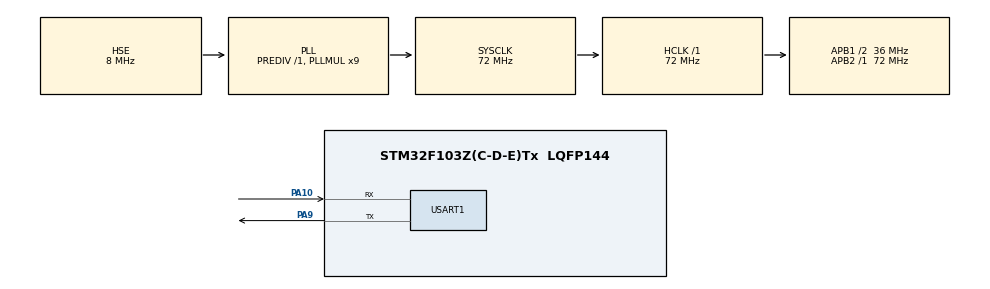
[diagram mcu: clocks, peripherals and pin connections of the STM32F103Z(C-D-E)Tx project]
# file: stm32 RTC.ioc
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Mcu.Family=STM32F1
Mcu.Name=STM32F103Z(C-D-E)Tx
Mcu.Package=LQFP144
NVIC.PriorityGroup=NVIC_PRIORITYGROUP_4
NVIC.RTC_Alarm_IRQn=true\:0\:0\:false\:false\:true\:true\:true
NVIC.RTC_IRQn=true\:0\:0\:false\:false\:true\:true\:true
NVIC.USART1_IRQn=true\:0\:0\:false\:false\:true\:true\:true
OSC_IN.Mode=HSE-External-Oscillator
OSC_IN.Signal=RCC_OSC_IN
OSC_OUT.Mode=HSE-External-Oscillator
OSC_OUT.Signal=RCC_OSC_OUT
PA10.Mode=Asynchronous
PA10.Signal=USART1_RX
PA9.Mode=Asynchronous
PA9.Signal=USART1_TX
ProjectManager.HeapSize=0x200
ProjectManager.StackSize=0x400
ProjectManager.TargetToolchain=MDK-ARM V5.32
RCC.AHBFreq_Value=72000000
RCC.APB1CLKDivider=RCC_HCLK_DIV2
RCC.APB1Freq_Value=36000000
RCC.APB1TimFreq_Value=72000000
RCC.APB2Freq_Value=72000000
RCC.APB2TimFreq_Value=72000000
RCC.HCLKFreq_Value=72000000
RCC.PLLMUL=RCC_PLL_MUL9
RCC.PLLSourceVirtual=RCC_PLLSOURCE_HSE
RCC.SYSCLKFreq_VALUE=72000000
RCC.SYSCLKSource=RCC_SYSCLKSOURCE_PLLCLK
RCC.USBFreq_Value=72000000
RTC.Date=14
RTC.Hours=10
RTC.WeekDay=RTC_WEEKDAY_SATURDAY
USART1.VirtualMode=VM_ASYNC
VP_RTC_VS_RTC_Activate.Mode=RTC_Enabled
VP_RTC_VS_RTC_Calendar.Mode=RTC_Calendar
VP_SYS_VS_ND.Mode=No_Debug
board=custom

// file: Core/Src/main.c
/* USER CODE BEGIN Header */
/**
  ******************************************************************************
  * @file           : main.c
  * @brief          : Main program body
  ******************************************************************************
  * @attention
  *
  * Copyright (c) 2023 STMicroelectronics.
  * All rights reserved.
  *
  * This software is licensed under terms that can be found in the LICENSE file
  * in the root directory of this software component.
  * If no LICENSE file comes with this software, it is provided AS-IS.
  *
  ******************************************************************************
  */
/* USER CODE END Header */
#include "main.h"
#include "rtc.h"
#include "usart.h"
#include "gpio.h"

/* USER CODE BEGIN Includes */
#include "stdio.h"
#include "string.h"
/* USER CODE END Includes */

/* USER CODE BEGIN PTD */
RTC_TimeTypeDef RtcTime;
RTC_DateTypeDef RtcDate;

const char LedMode1[8] = "kaishi";
const char LedMode2[11] = "chushihua";
const char LedMode3[14] = "shezhi12311111";
const char LedMode4[9] = "xianshi";

#define RXBUFFERSIZE  256     //最大接收字节数
char RxBuffer[RXBUFFERSIZE];   //接收数据
uint8_t aRxBuffer;			//接收中断缓冲
uint8_t Uart1_Rx_Cnt = 0;		//接收缓冲计数

/* USER CODE END PTD */

void SystemClock_Config(void);

int main(void)
{

  /* MCU Configuration--------------------------------------------------------*/

  /* Reset of all peripherals, Initializes the Flash interface and the Systick. */
  HAL_Init();

  /* Configure the system clock */
  SystemClock_Config();

  /* Initialize all configured peripherals */
  MX_GPIO_Init();
  MX_RTC_Init();
  MX_USART1_UART_Init();
  /* USER CODE BEGIN 2 */

 HAL_UART_Receive_IT(&huart1, (uint8_t *)&aRxBuffer, 1);

  /* USER CODE END 2 */

  /* Infinite loop */
  while (1)
  {

  }
}

void SystemClock_Config(void)
{
  RCC_OscInitTypeDef RCC_OscInitStruct = {0};
  RCC_ClkInitTypeDef RCC_ClkInitStruct = {0};
  RCC_PeriphCLKInitTypeDef PeriphClkInit = {0};

  /** Initializes the RCC Oscillators according to the specified parameters
  * in the RCC_OscInitTypeDef structure.
  */
  RCC_OscInitStruct.OscillatorType = RCC_OSCILLATORTYPE_LSI|RCC_OSCILLATORTYPE_HSE;
  RCC_OscInitStruct.HSEState = RCC_HSE_ON;
  RCC_OscInitStruct.HSEPredivValue = RCC_HSE_PREDIV_DIV1;
  RCC_OscInitStruct.HSIState = RCC_HSI_ON;
  RCC_OscInitStruct.LSIState = RCC_LSI_ON;
  RCC_OscInitStruct.PLL.PLLState = RCC_PLL_ON;
  RCC_OscInitStruct.PLL.PLLSource = RCC_PLLSOURCE_HSE;
  RCC_OscInitStruct.PLL.PLLMUL = RCC_PLL_MUL9;
  if (HAL_RCC_OscConfig(&RCC_OscInitStruct) != HAL_OK)
  {
    Error_Handler();
  }
  /** Initializes the CPU, AHB and APB buses clocks
  */
  RCC_ClkInitStruct.ClockType = RCC_CLOCKTYPE_HCLK|RCC_CLOCKTYPE_SYSCLK
                              |RCC_CLOCKTYPE_PCLK1|RCC_CLOCKTYPE_PCLK2;
  RCC_ClkInitStruct.SYSCLKSource = RCC_SYSCLKSOURCE_PLLCLK;
  RCC_ClkInitStruct.AHBCLKDivider = RCC_SYSCLK_DIV1;
  RCC_ClkInitStruct.APB1CLKDivider = RCC_HCLK_DIV2;
  RCC_ClkInitStruct.APB2CLKDivider = RCC_HCLK_DIV1;

  if (HAL_RCC_ClockConfig(&RCC_ClkInitStruct, FLASH_LATENCY_2) != HAL_OK)
  {
    Error_Handler();
  }
  PeriphClkInit.PeriphClockSelection = RCC_PERIPHCLK_RTC;
  PeriphClkInit.RTCClockSelection = RCC_RTCCLKSOURCE_LSI;
  if (HAL_RCCEx_PeriphCLKConfig(&PeriphClkInit) != HAL_OK)
  {
    Error_Handler();
  }
}

/* USER CODE BEGIN 4 */
void HAL_RTCEx_RTCEventCallback(RTC_HandleTypeDef *hrtc)
{

	HAL_RTC_GetTime(&*hrtc,&RtcTime,RTC_FORMAT_BIN);//获取时间
  HAL_RTC_GetDate(&*hrtc,&RtcDate,RTC_FORMAT_BIN);//获取日期

  printf("time:%2d:%2d:%2d\r\n",RtcTime.Hours,RtcTime.Minutes,RtcTime.Seconds);
  printf("data:%4d.%2d.%2d\r\n",2000+RtcDate.Year,RtcDate.Month,RtcDate.Date);

}
void HAL_UART_RxCpltCallback(UART_HandleTypeDef *huart)
{
	UNUSED(huart);
	//if(Uart1_Rx_Cnt >= 255)  //溢出判断
	//{
		//Uart1_Rx_Cnt = 0;
		//memset(RxBuffer,0x00,sizeof(RxBuffer));
		//HAL_UART_Transmit(&huart1, (uint8_t *)"数据溢出", 10,0xFFFF);
		//printf("数据溢出");
	//}
	//else
	//{
		RxBuffer[Uart1_Rx_Cnt++] = aRxBuffer;   //接收数据转存

		if((RxBuffer[Uart1_Rx_Cnt-1] == 0x0A)&&(RxBuffer[Uart1_Rx_Cnt-2] == 0x0D)) //判断结束位
		{
			//HAL_UART_Transmit(&huart1, (uint8_t *)&RxBuffer, Uart1_Rx_Cnt,0xFFFF); //将收到的信息发送出去
			Uart1_Rx_Cnt = 0;
			if(strstr((const char *)RxBuffer,LedMode1) != NULL)
			{
				 HAL_RTC_GetTime(&hrtc, &RtcTime,  RTC_FORMAT_BIN);//读出时间值
				 HAL_RTC_GetDate(&hrtc, &RtcDate,  RTC_FORMAT_BIN);//一定要先读时间后读日期
				 printf(" 开发板RTC实时时钟测试   \r\n");
				 printf(" 实时时间：%04d-%02d-%02d  %02d:%02d:%02d  \r\n",2000+RtcDate.Year,
				 RtcDate.Month, RtcDate.Date,RtcTime.Hours, RtcTime.Minutes, RtcTime.Seconds);//显示日期时间
				 printf(" 单按回车键更新时间，输入字母C初始化时钟 \r\n");
				 printf(" 请输入设置时间，格式20170806120000，按回车键确定！ \r\n");

			}
			if(strstr((const char *)RxBuffer,LedMode2) != NULL)
			{
	  	          MX_RTC_Init(); //键盘输入c或C，初始化时钟
	  	          printf("初始化成功！       \r\n");//显示初始化成功
			}
			if(strlen((const char *)RxBuffer) == 16)
			{
				  RtcDate.Year =  (RxBuffer[2]-0x30)*10+RxBuffer[3]-0x30;//减0x30后才能得到十进制0~9的数据
				  RtcDate.Month =  (RxBuffer[4]-0x30)*10+RxBuffer[5]-0x30;
				  RtcDate.Date =  (RxBuffer[6]-0x30)*10+RxBuffer[7]-0x30;
				  RtcTime.Hours =  (RxBuffer[8]-0x30)*10+RxBuffer[9]-0x30;
				  RtcTime.Minutes =  (RxBuffer[10]-0x30)*10+RxBuffer[11]-0x30;
				  RtcTime.Seconds =  (RxBuffer[12]-0x30)*10+RxBuffer[13]-0x30;
				  if (HAL_RTC_SetTime(&hrtc,  &RtcTime, RTC_FORMAT_BIN) != HAL_OK)//将数据写入RTC程序
				  {
					  printf("写入时间失败！        \r\n"); //显示写入失败
				  }
				  else if (HAL_RTC_SetDate(&hrtc,  &RtcDate, RTC_FORMAT_BIN) != HAL_OK)//将数据写入RTC程序
				  {
					  printf("写入日期失败！        \r\n"); //显示写入失败
				  }
				  else
				  {
					  printf("写入成功！       \r\n");//显示写入成功
					  __HAL_RTC_SECOND_ENABLE_IT(&hrtc,RTC_IT_SEC);

				  }

			}
			if(strstr((const char *)RxBuffer,LedMode4) != NULL)
			{
					  __HAL_RTC_SECOND_ENABLE_IT(&hrtc,RTC_IT_SEC);
			}
			memset(RxBuffer,0x00,sizeof(RxBuffer)); //清空数组
		}
	//}

	HAL_UART_Receive_IT(&huart1, (uint8_t *)&aRxBuffer, 1);   //再开启接收中断

}
/* USER CODE END 4 */

void Error_Handler(void)
{
  __disable_irq();
  while (1)
  {
  }
}
